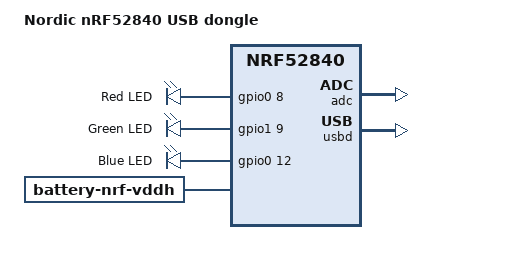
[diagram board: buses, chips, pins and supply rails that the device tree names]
/*
 * Copyright (c) 2020 The ZMK Contributors
 *
 * SPDX-License-Identifier: MIT
 */

/dts-v1/;
#include <nordic/nrf52840_qiaa.dtsi>

/ {
	model = "Nordic nRF52840 USB dongle";
	compatible = "nrf52840_dongle";

	chosen {
		zephyr,code-partition = &code_partition;
		zephyr,sram = &sram0;
		zephyr,flash = &flash0;
		zephyr,console = &cdc_acm_uart;
		zmk,battery = &vbatt;
	};

	leds {
		compatible = "gpio-leds";
		red_led: led_0 {
			gpios = <&gpio0 8 GPIO_ACTIVE_HIGH>;
			label = "Red LED";
		};
		green_led: led_1 {
			gpios = <&gpio1 9 GPIO_ACTIVE_HIGH>;
			label = "Green LED";
		};
		blue_led: led_2 {
			gpios = <&gpio0 12 GPIO_ACTIVE_HIGH>;
			label = "Blue LED";
		};
	};

	vbatt: vbatt {
		compatible = "zmk,battery-nrf-vddh";
		label = "BATTERY";
	};

};

&adc {
	status = "okay";
};

&gpiote {
	status = "okay";
};

&gpio0 {
	status = "okay";
};

&gpio1 {
	status = "okay";
};

&usbd {
	compatible = "nordic,nrf-usbd";
	status = "okay";
	cdc_acm_uart: cdc_acm_uart {
		compatible = "zephyr,cdc-acm-uart";
		label = "CDC_ACM_0";
	};
};


&flash0 {
	/*
	 * For more information, see:
	 * http://docs.zephyrproject.org/latest/devices/dts/flash_partitions.html
	 */
	partitions {
		compatible = "fixed-partitions";
		#address-cells = <1>;
		#size-cells = <1>;

		sd_partition: partition@0 {
			label = "softdevice";
			reg = <0x00001000 0x00026000>;
		};
		code_partition: partition@27000 {
			label = "code_partition";
			reg = <0x00027000 0x000b1000>;
		};

		/*
		 * Storage partition will be used by FCB/LittleFS/NVS
		 * if enabled.
		 */
		storage_partition: partition@ec000 {
			label = "storage";
			reg = <0x000d8000 0x00008000>;
		};

		boot_partition: partition@f4000 {
			label = "nordic_boot";
			reg = <0x000e0000 0x00020000>;
		};
	};
};
